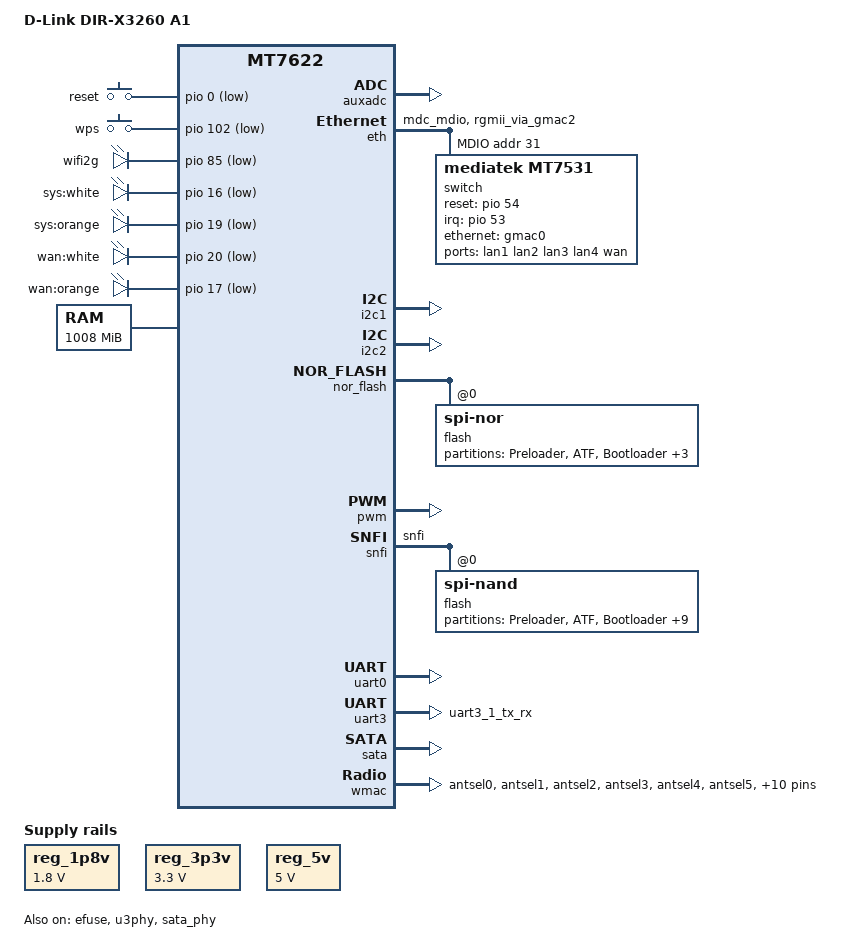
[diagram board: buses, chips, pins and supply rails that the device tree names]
// SPDX-License-Identifier: GPL-2.0
// SPDX-FileCopyrightText: 2017 MediaTek Inc.

/dts-v1/;
#include "mt7622.dtsi"
#include "mt6380.dtsi"
#include <dt-bindings/gpio/gpio.h>
#include <dt-bindings/input/input.h>

/ {
	model = "D-Link DIR-X3260 A1";
	compatible = "dlink,dir-x3260-a1", "mediatek,mt7622";

	chosen {
		bootargs = "console=ttyS0,115200n1 loglevel=8 swiotlb=512 \
				rootfstype=squashfs";
	};

	cpus {
		cpu@0 {
			proc-supply = <&mt6380_vcpu_reg>;
			sram-supply = <&mt6380_vm_reg>;
		};

		cpu@1 {
			proc-supply = <&mt6380_vcpu_reg>;
			sram-supply = <&mt6380_vm_reg>;
		};
	};

	gpio-keys {
		compatible = "gpio-keys";

		reset {
			label = "reset";
			gpios = <&pio 0 GPIO_ACTIVE_LOW>;
			linux,code = <KEY_RESTART>;
		};

		wps {
			label = "wps";
			gpios = <&pio 102 GPIO_ACTIVE_LOW>;
			linux,code = <KEY_WPS_BUTTON>;
		};
	};

	leds {
		compatible = "gpio-leds";

		wifi2g {
			label = "wifi2g";
			gpios = <&pio 85 GPIO_ACTIVE_LOW>;
		};

		syswhite {
			label = "sys:white";
			gpios = <&pio 16 GPIO_ACTIVE_LOW>;
		};

		sysorange {
			label = "sys:orange";
			gpios = <&pio 19 GPIO_ACTIVE_LOW>;
		};

		wanwhite {
			label = "wan:white";
			gpios = <&pio 20 GPIO_ACTIVE_LOW>;
		};

		wanorange {
			label = "wan:orange";
			gpios = <&pio 17 GPIO_ACTIVE_LOW>;
		};
	};

	reg_1p8v: regulator-1p8v {
		compatible = "regulator-fixed";
		regulator-name = "fixed-1.8V";
		regulator-min-microvolt = <1800000>;
		regulator-max-microvolt = <1800000>;
		regulator-always-on;
	};

	reg_3p3v: regulator-3p3v {
		compatible = "regulator-fixed";
		regulator-name = "fixed-3.3V";
		regulator-min-microvolt = <3300000>;
		regulator-max-microvolt = <3300000>;
		regulator-boot-on;
		regulator-always-on;
	};

	reg_5v: regulator-5v {
		compatible = "regulator-fixed";
		regulator-name = "fixed-5V";
		regulator-min-microvolt = <5000000>;
		regulator-max-microvolt = <5000000>;
		regulator-boot-on;
		regulator-always-on;
	};

	memory@40000000 {
		reg = <0 0x40000000 0 0x3F000000>;
		device_type = "memory";
	};
};

&auxadc {
	status = "okay";
};

&efuse {
	status = "okay";
};

&eth {
	pinctrl-names = "default";
	pinctrl-0 = <&eth_pins>;
	status = "okay";

	gmac0: mac@0 {
		compatible = "mediatek,eth-mac";
		reg = <0>;
		phy-mode = "2500base-x";
		nvmem-cells = <&macaddr_factory_28>;
		nvmem-cell-names = "mac-address";

		fixed-link {
			speed = <2500>;
			full-duplex;
			pause;
		};
	};

	mdio-bus {
		#address-cells = <1>;
		#size-cells = <0>;

		switch@1f {
			compatible = "mediatek,mt7531";
			reg = <31>;
			interrupt-controller;
			#interrupt-cells = <1>;
			interrupt-parent = <&pio>;
			interrupts = <53 IRQ_TYPE_LEVEL_HIGH>;
			reset-gpios = <&pio 54 0>;

			ports {
				#address-cells = <1>;
				#size-cells = <0>;

				port@0 {
					reg = <0>;
					label = "lan1";
				};

				port@1 {
					reg = <1>;
					label = "lan2";
				};

				port@2 {
					reg = <2>;
					label = "lan3";
				};

				port@3 {
					reg = <3>;
					label = "lan4";
				};

				wan: port@4 {
					reg = <4>;
					label = "wan";
					nvmem-cells = <&macaddr_factory_22>;
					nvmem-cell-names = "mac-address";
				};

				port@6 {
					reg = <6>;
					ethernet = <&gmac0>;
					phy-mode = "2500base-x";

					fixed-link {
						speed = <2500>;
						full-duplex;
						pause;
					};
				};
			};
		};

	};
};

&i2c1 {
	status = "okay";
};

&i2c2 {
	status = "okay";
};

&nor_flash {
	status = "okay";
	flash@0 {
		compatible = "jedec,spi-nor";
		#address-cells = <1>;
		#size-cells = <1>;
		partition@00000 {
			label = "Preloader";
			reg = <0x00000 0x0040000>;
		};
		partition@40000 {
			label = "ATF";
			reg = <0x40000 0x0020000>;
		};
		partition@60000 {
			label = "Bootloader";
			reg = <0x60000 0x0040000>;
		};
		partition@A0000 {
			label = "Config";
			reg = <0xA0000 0x0020000>;
		};
		partition@C0000 {
			label = "Factory";
			reg = <0xC0000 0x0080000>;
		};
		partition@E0000 {
			label = "Kernel";
			reg = <0x140000 0xEC0000>;
		};
	};
};

&pio {
	/* Serial NAND is shared pin with SPI-NOR */
	serial_nand_pins: serial-nand-pins {
		mux {
			function = "flash";
			groups = "snfi";
		};
	};

	uart3_pins: uart3-pins {
		mux {
			function = "uart";
			groups = "uart3_1_tx_rx" ;
		};
	};

	epa_elna_pins: epa-elna-pins {
		mux {
			function = "antsel";
			groups = "antsel0", "antsel1", "antsel2", "antsel3",
				"antsel4", "antsel5", "antsel6", "antsel7",
				"antsel8", "antsel9", "antsel12", "antsel13",
				"antsel14", "antsel15", "antsel16", "antsel17";
		};
	};

	eth_pins: eth-pins {
		mux {
			function = "eth";
			groups = "mdc_mdio", "rgmii_via_gmac2";
		};
	};

};

&pwm {
	status = "okay";
};

&snfi {
	pinctrl-names = "default";
	pinctrl-0 = <&serial_nand_pins>;
	status = "okay";

	flash@0 {
		compatible = "spi-nand";
		mediatek,bmt-table-size = <0x1000>;
		mediatek,bmt-v2;
		nand-ecc-engine = <&snfi>;
		reg = <0>;
		spi-rx-bus-width = <4>;
		spi-tx-bus-width = <4>;

		partitions {
			compatible = "fixed-partitions";
			#address-cells = <1>;
			#size-cells = <1>;

			partition@0 {
				label = "Preloader";
				reg = <0x00000 0x0080000>;
				read-only;
			};

			partition@80000 {
				label = "ATF";
				reg = <0x80000 0x0040000>;
			};

			partition@c0000 {
				label = "Bootloader";
				reg = <0xc0000 0x0080000>;
			};

			partition@140000 {
				label = "Config";
				reg = <0x140000 0x0080000>;
			};

			factory: partition@1c0000 {
				label = "Factory";
				reg = <0x1c0000 0x0100000>;
				read-only;

				nvmem-layout {
					compatible = "fixed-layout";
					#address-cells = <1>;
					#size-cells = <1>;

					macaddr_factory_22: macaddr@22 {
						reg = <0x22 0x6>;
					};

					macaddr_factory_28: macaddr@28 {
						reg = <0x28 0x6>;
					};
				};
			};

			partition@2C0000 {
				label = "Config2";
				reg = <0x2C0000 0x40000>;
			};

			partition@300000 {
				label = "firmware";
				reg = <0x300000 0x2000000>;
			};

			partition@2300000 {
				label = "firmware2";
				reg = <0x2300000 0x2000000>;
			};
			
			partition@4300000 {
				label = "rootfs_data";
				reg = <0x4300000 0xA00000>;
			};

			partition@4D00000 {
				label = "Private";
				reg = <0x4D00000 0x1400000>;
			};

			partition@6100000 {
				label = "mydlink";
				reg = <0x6100000 0x600000>;
			};

			partition@6700000 {
				label = "myconfig";
				reg = <0x6700000 0xA00000>;
			};
		};
	};
};

&uart0 {
	status = "okay";
};
 
&uart3 {
	pinctrl-names = "default";
	pinctrl-0 = <&uart3_pins>;
	status = "okay";
};

&u3phy {
	status = "okay";
};

&sata {
	status = "okay";
};

&sata_phy {
	status = "okay";
};

&wmac {
	pinctrl-names = "default";
	pinctrl-0 = <&epa_elna_pins>;
	mediatek,mtd-eeprom = <&factory 0x0000>;
	status = "okay";
};

